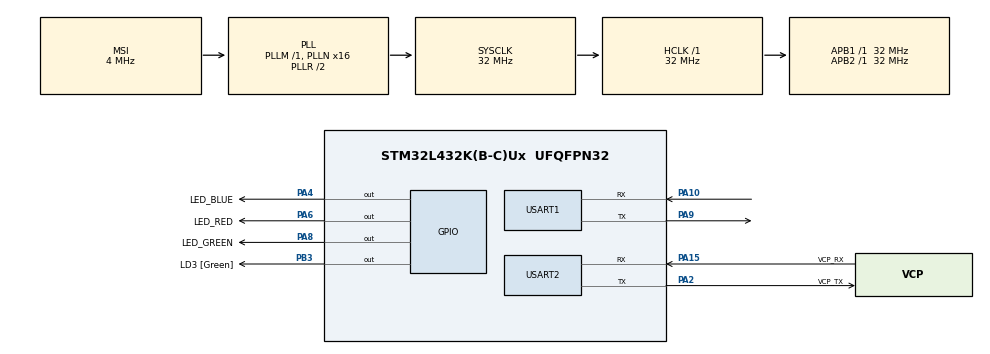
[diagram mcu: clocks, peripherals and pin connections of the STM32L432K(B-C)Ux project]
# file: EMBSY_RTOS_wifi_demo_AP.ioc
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FREERTOS.Tasks01=defaultTask,24,128,StartDefaultTask,Default,NULL,Dynamic,NULL,NULL
FREERTOS.configUSE_NEWLIB_REENTRANT=1
Mcu.Family=STM32L4
Mcu.Name=STM32L432K(B-C)Ux
Mcu.Package=UFQFPN32
NVIC.PriorityGroup=NVIC_PRIORITYGROUP_4
NVIC.TIM6_DAC_IRQn=true\:15\:0\:false\:false\:true\:false\:false\:true\:true
NVIC.TimeBase=TIM6_DAC_IRQn
NVIC.TimeBaseIP=TIM6
NVIC.USART1_IRQn=true\:5\:0\:false\:false\:true\:true\:true\:true\:true
NVIC.USART2_IRQn=true\:5\:0\:false\:false\:true\:true\:true\:true\:true
PA0.GPIO_Label=MCO [High speed clock in]
PA0.Mode=HSE-External-Clock-Source-for-LittleOrca
PA0.Signal=RCC_CK_IN
PA10.Mode=Asynchronous
PA10.Signal=USART1_RX
PA13\ (JTMS-SWDIO).GPIO_Label=SWDIO
PA13\ (JTMS-SWDIO).Mode=Serial_Wire
PA13\ (JTMS-SWDIO).Signal=SYS_JTMS-SWDIO
PA14\ (JTCK-SWCLK).GPIO_Label=SWCLK
PA14\ (JTCK-SWCLK).Mode=Serial_Wire
PA14\ (JTCK-SWCLK).Signal=SYS_JTCK-SWCLK
PA15\ (JTDI).GPIO_Label=VCP_RX
PA15\ (JTDI).Mode=Asynchronous
PA15\ (JTDI).Signal=USART2_RX
PA2.GPIO_Label=VCP_TX
PA2.Mode=Asynchronous
PA2.Signal=USART2_TX
PA4.GPIO_Label=LED_BLUE
PA4.Signal=GPIO_Output
PA6.GPIO_Label=LED_RED
PA6.Signal=GPIO_Output
PA8.GPIO_Label=LED_GREEN
PA8.Signal=GPIO_Output
PA9.Mode=Asynchronous
PA9.Signal=USART1_TX
PB3\ (JTDO-TRACESWO).GPIO_Label=LD3 [Green]
PB3\ (JTDO-TRACESWO).Signal=GPIO_Output
PC14-OSC32_IN\ (PC14).Mode=LSE-External-Oscillator
PC14-OSC32_IN\ (PC14).Signal=RCC_OSC32_IN
PC15-OSC32_OUT\ (PC15).Mode=LSE-External-Oscillator
PC15-OSC32_OUT\ (PC15).Signal=RCC_OSC32_OUT
ProjectManager.HeapSize=0x200
ProjectManager.StackSize=0x400
ProjectManager.TargetToolchain=STM32CubeIDE
RCC.AHBFreq_Value=32000000
RCC.APB1Freq_Value=32000000
RCC.APB1TimFreq_Value=32000000
RCC.APB2Freq_Value=32000000
RCC.APB2TimFreq_Value=32000000
RCC.CortexFreq_Value=32000000
RCC.HCLKFreq_Value=32000000
RCC.HSE_VALUE=8000000
RCC.HSI16_VALUE=16000000
RCC.HSI48_VALUE=48000000
RCC.HSI_VALUE=16000000
RCC.MSI_VALUE=4000000
RCC.PLLMUL=RCC_PLLMUL_4
RCC.PLLN=16
RCC.SYSCLKFreq_VALUE=32000000
RCC.SYSCLKSource=RCC_SYSCLKSOURCE_PLLCLK
RCC.VCOOutputFreq_Value=64000000
USART1.VirtualMode-Asynchronous=VM_ASYNC
USART2.VirtualMode-Asynchronous=VM_ASYNC
VP_FREERTOS_VS_CMSIS_V2.Mode=CMSIS_V2
VP_SYS_VS_tim6.Mode=TIM6
board=NUCLEO-L432KC

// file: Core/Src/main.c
/* USER CODE BEGIN Header */
/**
 ******************************************************************************
 * @file           : main.c
 * @brief          : WiFi-Click AP-DEMO
 *
 * A very simple and brief WiFi-Click demonstration to transfer commands via TCP
 * 	--> WARNING! THIS IS A DEMO IMPLEMENTATION! DOES NOT FEATURE ALL ERROR HANDLING / CHECKS!!!
 *
 ******************************************************************************
 * @attention
 *
 * ## Demonstration Overview
 *
 * This example demonstrates how the WiFi-click can be initialized and configured to handle simple TCP commands.
 * It does not utilize FreeRTOS in any way - everything is running in a single task without any communication.
 * It basically acts as a "standard" application without RTOS. There is also no error handling implemented.
 * Those are the things you will have to to do on your own to improve this code.
 *
 * The bare minimum UART implementation is already done here. Receiving data is done via interrupt using the
 * "receive to idle" functionality.
 *
 * Regarding the UART --> BE CAREFUL WITH BUFFEROVERFLOWS!
 * The wifi-click is very "noisy" and will spit out a lot of data via its UART interface. This can easily overflow the UART buffer.
 * Therefore this application uses a flushing mechanism. However, if something is lost it is not detected. No retry is implemented either.
 * (think of a better solution here!)
 *
 * The response of the WiFi-Click is not really monitored yet.
 *
 * This application relies on delays which is really not good. This results in a very slow application as there is some kind of safety margin
 * in the delays so the WiFi-Click has a chance to response.
 * Be patient! It takes some time until the initialization is complete!
 *
 ******************************************************************************
 */
/* USER CODE END Header */
#include "main.h"
#include "cmsis_os.h"
#include "usart.h"
#include "gpio.h"

/* USER CODE BEGIN Includes */
#include <stdio.h>

#include "../custom_middleware/01_helper_functions/helper_functions.h"
#include "../custom_middleware/99_tasks/wifi_task/wifi_task.h"
/* USER CODE END Includes */

void SystemClock_Config(void);
void MX_FREERTOS_Init(void);

int main(void)
{

  /* MCU Configuration--------------------------------------------------------*/

  /* Reset of all peripherals, Initializes the Flash interface and the Systick. */
  HAL_Init();

  /* Configure the system clock */
  SystemClock_Config();

  /* Initialize all configured peripherals */
  MX_GPIO_Init();
  MX_USART2_UART_Init();
  MX_USART1_UART_Init();
  /* USER CODE BEGIN 2 */
	HAL_GPIO_WritePin(WIFI_CS_GPIO_Port, WIFI_CS_Pin, 1); //set Chip-Select Pin of the Wifi-Click
	printf("***************************************EMBSY - FREERTOS WIFI AP-MODE DEMO - START - WAITING 5 SECONDS*****************************************\r\n");
	all_leds_off();
	HAL_Delay(5000);
	init_led_timer();
	init_wifi_task();
  /* USER CODE END 2 */

  /* Init scheduler */
  osKernelInitialize();  /* Call init function for freertos objects (in freertos.c) */
  MX_FREERTOS_Init();

  /* Start scheduler */
  osKernelStart();

  /* We should never get here as control is now taken by the scheduler */
  /* Infinite loop */
	while (1)
	{

	}
}

void SystemClock_Config(void)
{
  RCC_OscInitTypeDef RCC_OscInitStruct = {0};
  RCC_ClkInitTypeDef RCC_ClkInitStruct = {0};

  /** Configure the main internal regulator output voltage
  */
  if (HAL_PWREx_ControlVoltageScaling(PWR_REGULATOR_VOLTAGE_SCALE1) != HAL_OK)
  {
    Error_Handler();
  }

  /** Configure LSE Drive Capability
  */
  HAL_PWR_EnableBkUpAccess();
  __HAL_RCC_LSEDRIVE_CONFIG(RCC_LSEDRIVE_LOW);

  /** Initializes the RCC Oscillators according to the specified parameters
  * in the RCC_OscInitTypeDef structure.
  */
  RCC_OscInitStruct.OscillatorType = RCC_OSCILLATORTYPE_LSE|RCC_OSCILLATORTYPE_MSI;
  RCC_OscInitStruct.LSEState = RCC_LSE_ON;
  RCC_OscInitStruct.MSIState = RCC_MSI_ON;
  RCC_OscInitStruct.MSICalibrationValue = 0;
  RCC_OscInitStruct.MSIClockRange = RCC_MSIRANGE_6;
  RCC_OscInitStruct.PLL.PLLState = RCC_PLL_ON;
  RCC_OscInitStruct.PLL.PLLSource = RCC_PLLSOURCE_MSI;
  RCC_OscInitStruct.PLL.PLLM = 1;
  RCC_OscInitStruct.PLL.PLLN = 16;
  RCC_OscInitStruct.PLL.PLLP = RCC_PLLP_DIV7;
  RCC_OscInitStruct.PLL.PLLQ = RCC_PLLQ_DIV2;
  RCC_OscInitStruct.PLL.PLLR = RCC_PLLR_DIV2;
  if (HAL_RCC_OscConfig(&RCC_OscInitStruct) != HAL_OK)
  {
    Error_Handler();
  }

  /** Initializes the CPU, AHB and APB buses clocks
  */
  RCC_ClkInitStruct.ClockType = RCC_CLOCKTYPE_HCLK|RCC_CLOCKTYPE_SYSCLK
                              |RCC_CLOCKTYPE_PCLK1|RCC_CLOCKTYPE_PCLK2;
  RCC_ClkInitStruct.SYSCLKSource = RCC_SYSCLKSOURCE_PLLCLK;
  RCC_ClkInitStruct.AHBCLKDivider = RCC_SYSCLK_DIV1;
  RCC_ClkInitStruct.APB1CLKDivider = RCC_HCLK_DIV1;
  RCC_ClkInitStruct.APB2CLKDivider = RCC_HCLK_DIV1;

  if (HAL_RCC_ClockConfig(&RCC_ClkInitStruct, FLASH_LATENCY_1) != HAL_OK)
  {
    Error_Handler();
  }

  /** Enable MSI Auto calibration
  */
  HAL_RCCEx_EnableMSIPLLMode();
}

void HAL_TIM_PeriodElapsedCallback(TIM_HandleTypeDef *htim)
{
  if (htim->Instance == TIM6) {
    HAL_IncTick();
  }
}

void Error_Handler(void)
{
	__disable_irq();
	while (1)
	{
	}
}
